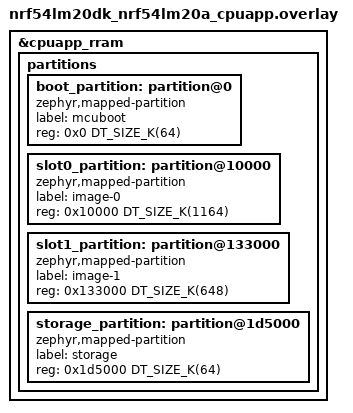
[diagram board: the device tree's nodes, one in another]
/*
 * Copyright (c) 2025 Nordic Semiconductor ASA
 *
 * SPDX-License-Identifier: LicenseRef-Nordic-5-Clause
 */

/delete-node/ &boot_partition;
/delete-node/ &slot0_partition;
/delete-node/ &slot1_partition;
/delete-node/ &storage_partition;

&cpuapp_rram {
	partitions {
		ranges;
		#address-cells = <1>;
		#size-cells = <1>;

		boot_partition: partition@0 {
			compatible = "zephyr,mapped-partition";
			label = "mcuboot";
			reg = <0x0 DT_SIZE_K(64)>;
		};

		slot0_partition: partition@10000 {
			compatible = "zephyr,mapped-partition";
			label = "image-0";
			reg = <0x10000 DT_SIZE_K(1164)>;
		};

		slot1_partition: partition@133000 {
			compatible = "zephyr,mapped-partition";
			label = "image-1";
			reg = <0x133000 DT_SIZE_K(648)>;
		};

		storage_partition: partition@1d5000 {
			compatible = "zephyr,mapped-partition";
			label = "storage";
			reg = <0x1d5000 DT_SIZE_K(64)>;
		};
	};
};
